# HTNB32L-XXX register map
File version: 0.9
CPU: CM3 r0p0, little endian, no MPU, no FPU, 3 interrupt priority bits
Registers are 32-bit, read-write, reset 0x0 unless marked. A register's access mark holds for its fields unless they carry their own. Offsets are from the block's base; [hi:lo] are bit positions; 'fields as' and 'values as' point back to an identical list.

## IOCON (part 2 of 3) — IOCON pin configuration
Base 0x4002C000
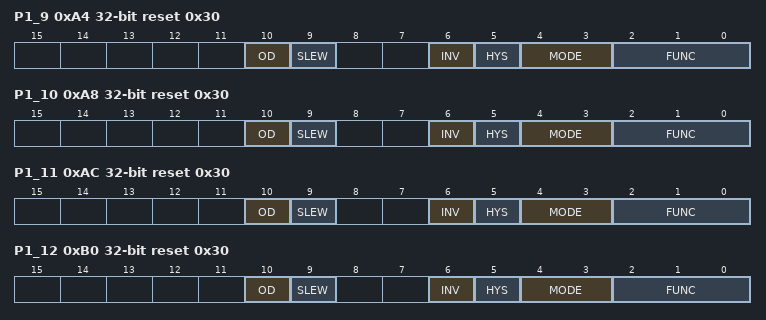
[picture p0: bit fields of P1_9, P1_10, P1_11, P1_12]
0xA4 P1_9 reset 0x30 — I/O configuration register for pin P1[9]
  [10] OD — Open-drain mode.
    0=DISABLE; 1=ENABLED (Open-drain mode enabled. This is not a true open-drain mode. Input cannot be pulled up above VDD.)
  [9] SLEW — Driver slew rate
    0=STANDARD (Standard mode, output slew rate control is enabled. More outputs can be switched simultaneously.); 1=FAST (Fast mode, slew rate control is disabled. Refer to the appropriate specific device data sheet for details.)
  [6] INV — Invert input
    0=INPUT_NOT_INVERTED (Input not inverted (HIGH on pin reads as 1, LOW on pin reads as 0).); 1=INPUT_INVERTED_HIGH (Input inverted (HIGH on pin reads as 0, LOW on pin reads as 1).)
  [5] HYS — Hysteresis.
    0=DISABLE; 1=ENABLE
  [4:3] MODE — Selects function mode (on-chip pull-up/pull-down resistor control).
    0=INACTIVE (Inactive (no pull-down/pull-up resistor enabled).); 1=PULLDOWN_EN (Pull-down resistor enabled.); 2=PULLUP_EN (Pull-up resistor enabled.); 3=REPEATER_MODE
  [2:0] FUNC — Selects pin function for pin P1[9]
    0=P1_9 (General purpose digital input/output pin.); 1=ENET_RXD0 (Ethernet receive data 0 (RMII/MII interface).); 3=T3_MAT0 (Match output for Timer 3, channel 0.)
0xA8 P1_10 reset 0x30 — I/O configuration register for pin P1[10]
  [10] OD — Open-drain mode.
    values as P1_9.OD
  [9] SLEW — Driver slew rate
    values as P1_9.SLEW
  [6] INV — Invert input
    values as P1_9.INV
  [5] HYS — Hysteresis.
    0=DISABLE; 1=ENABLE
  [4:3] MODE — Selects function mode (on-chip pull-up/pull-down resistor control).
    values as P1_9.MODE
  [2:0] FUNC — Selects pin function for pin P1[10]
    0=P1_10 (General purpose digital input/output pin.); 1=ENET_RXD1 (Ethernet receive data 1 (RMII/MII interface).); 3=T3_CAP0 (Capture input for Timer 3, channel 0.)
0xAC P1_11 reset 0x30 — I/O configuration register for pin P1[11]
  [10] OD — Open-drain mode.
    values as P1_9.OD
  [9] SLEW — Driver slew rate
    values as P1_9.SLEW
  [6] INV — Invert input
    values as P1_9.INV
  [5] HYS — Hysteresis.
    0=DISABLE; 1=ENABLE
  [4:3] MODE — Selects function mode (on-chip pull-up/pull-down resistor control).
    values as P1_9.MODE
  [2:0] FUNC — Selects pin function for pin P1[11]
    0=P1_11 (General purpose digital input/output pin.); 1=ENET_RXD2 (Ethernet Receive Data 2 (MII interface).); 2=SD_DAT_2 (Data line 2 for SD card interface.); 3=PWM0_6 (Pulse Width Modulator 0, output 6.)
0xB0 P1_12 reset 0x30 — I/O configuration register for pin P1[12]
  [10] OD — Open-drain mode.
    values as P1_9.OD
  [9] SLEW — Driver slew rate
    values as P1_9.SLEW
  [6] INV — Invert input
    values as P1_9.INV
  [5] HYS — Hysteresis.
    0=DISABLE; 1=ENABLE
  [4:3] MODE — Selects function mode (on-chip pull-up/pull-down resistor control).
    values as P1_9.MODE
  [2:0] FUNC — Selects pin function for pin P1[12]
    0=P1_12 (General purpose digital input/output pin.); 1=ENET_RXD3 (Ethernet Receive Data (MII interface).); 2=SD_DAT_3 (Data line 3 for SD card interface.); 3=PWM0_CAP0 (Capture input for PWM0, channel 0.)
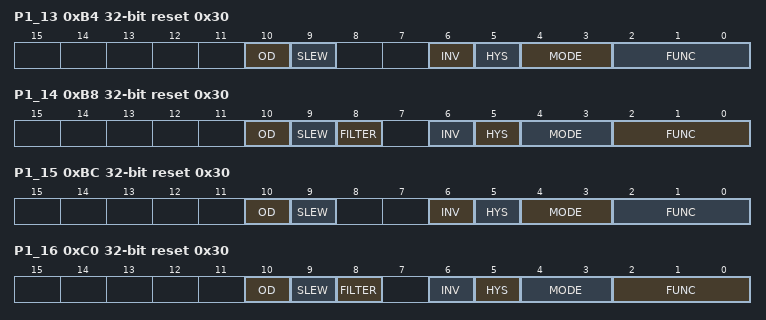
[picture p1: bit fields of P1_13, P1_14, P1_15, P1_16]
0xB4 P1_13 reset 0x30 — I/O configuration register for pin P1[13]
  [10] OD — Open-drain mode.
    values as P1_9.OD
  [9] SLEW — Driver slew rate
    values as P1_9.SLEW
  [6] INV — Invert input
    values as P1_9.INV
  [5] HYS — Hysteresis.
    0=DISABLE; 1=ENABLE
  [4:3] MODE — Selects function mode (on-chip pull-up/pull-down resistor control).
    values as P1_9.MODE
  [2:0] FUNC — Selects pin function for pin P1[13]
    0=P1_13 (General purpose digital input/output pin.); 1=ENET_RX_DV (Ethernet Receive Data Valid (MII interface).)
0xB8 P1_14 reset 0x30 — I/O configuration register for pin P1[14]
  [10] OD — Open-drain mode.
    values as P1_9.OD
  [9] SLEW — Driver slew rate
    values as P1_9.SLEW
  [8] FILTER — Glitch filter control
    0=ENABLED (Noise pulses below approximately 10 ns are filtered out.); 1=DISABLED (No input filtering is done.)
  [6] INV — Invert input
    values as P1_9.INV
  [5] HYS — Hysteresis.
    0=DISABLE; 1=ENABLE
  [4:3] MODE — Selects function mode (on-chip pull-up/pull-down resistor control).
    values as P1_9.MODE
  [2:0] FUNC — Selects pin function for pin P1[14]
    0=P1_14 (General purpose digital input/output pin.); 1=ENET_RX_ER (Ethernet receive error (RMII/MII interface).); 3=T2_CAP0 (Capture input for Timer 2, channel 0.)
0xBC P1_15 reset 0x30 — I/O configuration register for pin P1[15]
  [10] OD — Open-drain mode.
    values as P1_9.OD
  [9] SLEW — Driver slew rate
    values as P1_9.SLEW
  [6] INV — Invert input
    values as P1_9.INV
  [5] HYS — Hysteresis.
    0=DISABLE; 1=ENABLE
  [4:3] MODE — Selects function mode (on-chip pull-up/pull-down resistor control).
    values as P1_9.MODE
  [2:0] FUNC — Selects pin function for pin P1[15]
    0=P1_15 (General purpose digital input/output pin.); 1=ENET_RX_CLK_REF_CLK (Ethernet Receive Clock (MII interface) or Ethernet Reference Clock (RMII interface).); 3=I2C2_SDA (I2C2 data input/output (this pin does not use a specialized I2C pad).)
0xC0 P1_16 reset 0x30 — I/O configuration register for pin P1[16]
  [10] OD — Open-drain mode.
    values as P1_9.OD
  [9] SLEW — Driver slew rate
    values as P1_9.SLEW
  [8] FILTER — Glitch filter control
    values as P1_14.FILTER
  [6] INV — Invert input
    values as P1_9.INV
  [5] HYS — Hysteresis.
    0=DISABLE; 1=ENABLE
  [4:3] MODE — Selects function mode (on-chip pull-up/pull-down resistor control).
    values as P1_9.MODE
  [2:0] FUNC — Selects pin function for pin P1[16]
    0=P1_16 (General purpose digital input/output pin.); 1=ENET_MDC (Ethernet MIIM clock.); 2=I2S_TX_MCLK (I2S transmit master clock.)
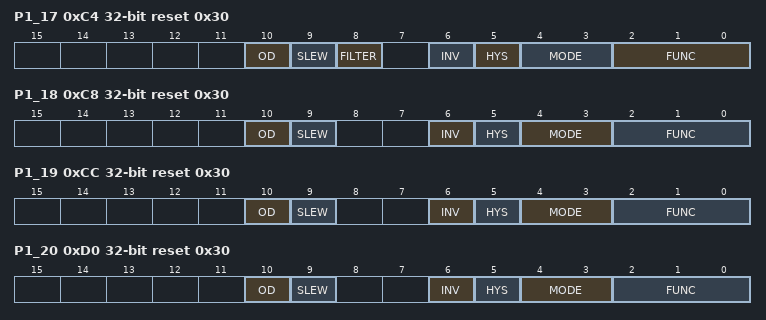
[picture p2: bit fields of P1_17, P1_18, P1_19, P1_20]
0xC4 P1_17 reset 0x30 — I/O configuration register for pin P1[17]
  [10] OD — Open-drain mode.
    values as P1_9.OD
  [9] SLEW — Driver slew rate
    values as P1_9.SLEW
  [8] FILTER — Glitch filter control
    values as P1_14.FILTER
  [6] INV — Invert input
    values as P1_9.INV
  [5] HYS — Hysteresis.
    0=DISABLE; 1=ENABLE
  [4:3] MODE — Selects function mode (on-chip pull-up/pull-down resistor control).
    values as P1_9.MODE
  [2:0] FUNC — Selects pin function for pin P1[17]
    0=P1_17 (General purpose digital input/output pin.); 1=ENET_MDIO (Ethernet MIIM data input and output.); 2=I2S_RX_MCLK (I2S receive master clock.)
0xC8 P1_18 reset 0x30 — I/O configuration register for pin P1[18]
  [10] OD — Open-drain mode.
    values as P1_9.OD
  [9] SLEW — Driver slew rate
    values as P1_9.SLEW
  [6] INV — Invert input
    values as P1_9.INV
  [5] HYS — Hysteresis.
    0=DISABLE; 1=ENABLE
  [4:3] MODE — Selects function mode (on-chip pull-up/pull-down resistor control).
    values as P1_9.MODE
  [2:0] FUNC — Selects pin function for pin P1[18]
    0=P1_18 (General purpose digital input/output pin.); 1=USB_UP_LED1 (It is LOW when the device is configured (non-control endpoints enabled), or when the host is enabled and has detected a device on the bus. It is HIGH when the device is not configured, or when host is enabled and has not detected a device on the bus, or during global suspend. It transitions between LOW and HIGH (flashes) when the host is enabled and detects activity on the bus.); 2=PWM1_1 (Pulse Width Modulator 1, channel 1 output.); 3=T1_CAP0 (Capture input for Timer 1, channel 0.); 5=SSP1_MISO (Master In Slave Out for SSP1.)
0xCC P1_19 reset 0x30 — I/O configuration register for pin P1[19]
  [10] OD — Open-drain mode.
    values as P1_9.OD
  [9] SLEW — Driver slew rate
    values as P1_9.SLEW
  [6] INV — Invert input
    values as P1_9.INV
  [5] HYS — Hysteresis.
    0=DISABLE; 1=ENABLE
  [4:3] MODE — Selects function mode (on-chip pull-up/pull-down resistor control).
    values as P1_9.MODE
  [2:0] FUNC — Selects pin function for pin P1[19]
    0=P1_19 (General purpose digital input/output pin.); 1=USB_TX_E1 (Transmit Enable signal for USB port 1 (OTG transceiver).); 2=USB_PPWR1 (Port Power enable signal for USB port 1.); 3=T1_CAP1 (Capture input for Timer 1, channel 1.); 4=MC_0A (Motor control PWM channel 0, output A.); 5=SSP1_SCK (Serial clock for SSP1.); 6=U2_OE (RS-485/EIA-485 output enable signal for UART2.)
0xD0 P1_20 reset 0x30 — I/O configuration register for pin P1[20]
  [10] OD — Open-drain mode.
    values as P1_9.OD
  [9] SLEW — Driver slew rate
    values as P1_9.SLEW
  [6] INV — Invert input
    values as P1_9.INV
  [5] HYS — Hysteresis.
    0=DISABLE; 1=ENABLE
  [4:3] MODE — Selects function mode (on-chip pull-up/pull-down resistor control).
    values as P1_9.MODE
  [2:0] FUNC — Selects pin function for pin P1[20]
    0=P1_20 (General purpose digital input/output pin.); 1=USB_TX_DP1 (D+ transmit data for USB port 1 (OTG transceiver).); 2=PWM1_2 (Pulse Width Modulator 1, channel 2 output.); 3=QEI_PHA (Quadrature Encoder Interface PHA input.); 4=MC_FB0 (Motor control PWM channel 0 feedback input.); 5=SSP0_SCK (Serial clock for SSP0.); 6=LCD_VD_6 (LCD data.); 7=LCD_VD_10 (LCD data.)
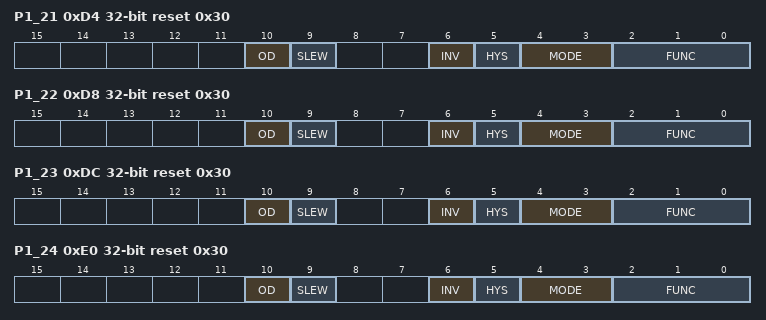
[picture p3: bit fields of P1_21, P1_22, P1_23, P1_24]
0xD4 P1_21 reset 0x30 — I/O configuration register for pin P1[21]
  [10] OD — Open-drain mode.
    values as P1_9.OD
  [9] SLEW — Driver slew rate
    values as P1_9.SLEW
  [6] INV — Invert input
    values as P1_9.INV
  [5] HYS — Hysteresis.
    0=DISABLE; 1=ENABLE
  [4:3] MODE — Selects function mode (on-chip pull-up/pull-down resistor control).
    values as P1_9.MODE
  [2:0] FUNC — Selects pin function for pin P1[21]
    0=P1_21 (General purpose digital input/output pin.); 1=USB_TX_DM1 (D- transmit data for USB port 1 (OTG transceiver).); 2=PWM1_3 (Pulse Width Modulator 1, channel 3 output.); 3=SSP0_SSEL (Slave Select for SSP0.); 4=MC_ABORT (Motor control PWM, active low fast abort.); 6=LCD_VD_7 (LCD data.); 7=LCD_VD_11 (LCD data.)
0xD8 P1_22 reset 0x30 — I/O configuration register for pin P1[22]
  [10] OD — Open-drain mode.
    values as P1_9.OD
  [9] SLEW — Driver slew rate
    values as P1_9.SLEW
  [6] INV — Invert input
    values as P1_9.INV
  [5] HYS — Hysteresis.
    0=DISABLE; 1=ENABLE
  [4:3] MODE — Selects function mode (on-chip pull-up/pull-down resistor control).
    values as P1_9.MODE
  [2:0] FUNC — Selects pin function for pin P1[22]
    0=P1_22 (General purpose digital input/output pin.); 1=USB_RCV1 (Differential receive data for USB port 1 (OTG transceiver).); 2=USB_PWRD1 (Power Status for USB port 1 (host power switch).); 3=T1_MAT0 (Match output for Timer 1, channel 0.); 4=MC_0B (Motor control PWM channel 0, output B.); 5=SSP1_MOSI (Master Out Slave In for SSP1.); 6=LCD_VD_8 (LCD data.); 7=LCD_VD_12 (LCD data.)
0xDC P1_23 reset 0x30 — I/O configuration register for pin P1[23]
  [10] OD — Open-drain mode.
    values as P1_9.OD
  [9] SLEW — Driver slew rate
    values as P1_9.SLEW
  [6] INV — Invert input
    values as P1_9.INV
  [5] HYS — Hysteresis.
    0=DISABLE; 1=ENABLE
  [4:3] MODE — Selects function mode (on-chip pull-up/pull-down resistor control).
    values as P1_9.MODE
  [2:0] FUNC — Selects pin function for pin P1[23]
    0=P1_23 (General purpose digital input/output pin.); 1=USB_RX_DP1 (D+ receive data for USB port 1 (OTG transceiver).); 2=PWM1_4 (Pulse Width Modulator 1, channel 4 output.); 3=QEI_PHB (Quadrature Encoder Interface PHB input.); 4=MC_FB1 (Motor control PWM channel 1 feedback input.); 5=SSP0_MISO (Master In Slave Out for SSP0.); 6=LCD_VD_9 (LCD data.); 7=LCD_VD_13 (LCD data.)
0xE0 P1_24 reset 0x30 — I/O configuration register for pin P1[24]
  [10] OD — Open-drain mode.
    values as P1_9.OD
  [9] SLEW — Driver slew rate
    values as P1_9.SLEW
  [6] INV — Invert input
    values as P1_9.INV
  [5] HYS — Hysteresis.
    0=DISABLE; 1=ENABLE
  [4:3] MODE — Selects function mode (on-chip pull-up/pull-down resistor control).
    values as P1_9.MODE
  [2:0] FUNC — Selects pin function for pin P1[24]
    0=P1_24 (General purpose digital input/output pin.); 1=USB_RX_DM1 (D- receive data for USB port 1 (OTG transceiver).); 2=PWM1_5 (Pulse Width Modulator 1, channel 5 output.); 3=QEI_IDX (Quadrature Encoder Interface INDEX input.); 4=MC_FB2 (Motor control PWM channel 2 feedback input.); 5=SSP0_MOSI (Master Out Slave in for SSP0.); 6=LCD_VD_10 (LCD data.); 7=LCD_VD_14 (LCD data.)
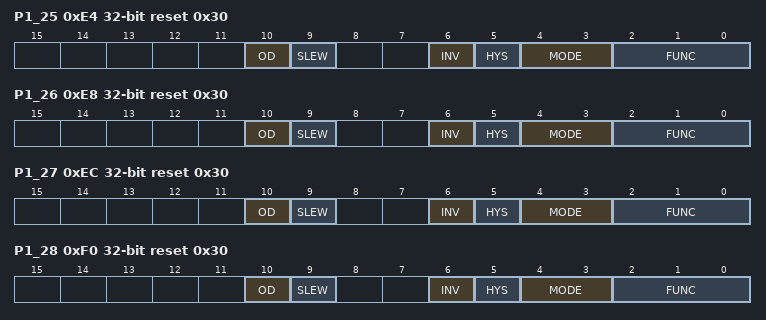
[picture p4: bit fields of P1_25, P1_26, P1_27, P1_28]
0xE4 P1_25 reset 0x30 — I/O configuration register for pin P1[25]
  [10] OD — Open-drain mode.
    values as P1_9.OD
  [9] SLEW — Driver slew rate
    values as P1_9.SLEW
  [6] INV — Invert input
    values as P1_9.INV
  [5] HYS — Hysteresis.
    0=DISABLE; 1=ENABLE
  [4:3] MODE — Selects function mode (on-chip pull-up/pull-down resistor control).
    values as P1_9.MODE
  [2:0] FUNC — Selects pin function for pin P1[25]
    0=P1_25 (General purpose digital input/output pin.); 1=USB_LS1 (Low Speed status for USB port 1 (OTG transceiver).); 2=USB_HSTEN1 (Host Enabled status for USB port 1.); 3=T1_MAT1 (Match output for Timer 1, channel 1.); 4=MC_1A (Motor control PWM channel 1, output A.); 5=CLKOUT (Selectable clock output.); 6=LCD_VD_11 (LCD data.); 7=LCD_VD_15 (LCD data.)
0xE8 P1_26 reset 0x30 — I/O configuration register for pin P1[26]
  [10] OD — Open-drain mode.
    values as P1_9.OD
  [9] SLEW — Driver slew rate
    values as P1_9.SLEW
  [6] INV — Invert input
    values as P1_9.INV
  [5] HYS — Hysteresis.
    0=DISABLE; 1=ENABLE
  [4:3] MODE — Selects function mode (on-chip pull-up/pull-down resistor control).
    values as P1_9.MODE
  [2:0] FUNC — Selects pin function for pin P1[26]
    0=P1_26 (General purpose digital input/output pin.); 1=USB_SSPND1 (USB port 1 Bus Suspend status (OTG transceiver).); 2=PWM1_6 (Pulse Width Modulator 1, channel 6 output.); 3=T0_CAP0 (Capture input for Timer 0, channel 0.); 4=MC_1B (Motor control PWM channel 1, output B.); 5=SSP1_SSEL (Slave Select for SSP1.); 6=LCD_VD_12 (LCD data.); 7=LCD_VD_20 (LCD data.)
0xEC P1_27 reset 0x30 — I/O configuration register for pin P1[27]
  [10] OD — Open-drain mode.
    values as P1_9.OD
  [9] SLEW — Driver slew rate
    values as P1_9.SLEW
  [6] INV — Invert input
    values as P1_9.INV
  [5] HYS — Hysteresis.
    0=DISABLE; 1=ENABLE
  [4:3] MODE — Selects function mode (on-chip pull-up/pull-down resistor control).
    values as P1_9.MODE
  [2:0] FUNC — Selects pin function for pin P1[27]
    0=P1_27 (General purpose digital input/output pin.); 1=USB_INT1 (USB port 1 OTG transceiver interrupt (OTG transceiver).); 2=USB_OVRCR1 (USB port 1 Over-Current status.); 3=T0_CAP1 (Capture input for Timer 0, channel 1.); 4=CLKOUT (Selectable clock output.); 6=LCD_VD_13 (LCD data.); 7=LCD_VD_21 (LCD data.)
0xF0 P1_28 reset 0x30 — I/O configuration register for pin P1[28]
  [10] OD — Open-drain mode.
    values as P1_9.OD
  [9] SLEW — Driver slew rate
    values as P1_9.SLEW
  [6] INV — Invert input
    values as P1_9.INV
  [5] HYS — Hysteresis.
    0=DISABLE; 1=ENABLE
  [4:3] MODE — Selects function mode (on-chip pull-up/pull-down resistor control).
    values as P1_9.MODE
  [2:0] FUNC — Selects pin function for pin P1[28]
    0=P1_28 (General purpose digital input/output pin.); 1=USB_SCL1 (USB port 1 I2C serial clock (OTG transceiver).); 2=PWM1_CAP0 (Capture input for PWM1, channel 0.); 3=T0_MAT0 (Match output for Timer 0, channel 0.); 4=MC_2A (Motor control PWM channel 2, output A.); 5=SSP0_SSEL (Slave Select for SSP0.); 6=LCD_VD_14 (LCD data.); 7=LCD_VD_22 (LCD data.)
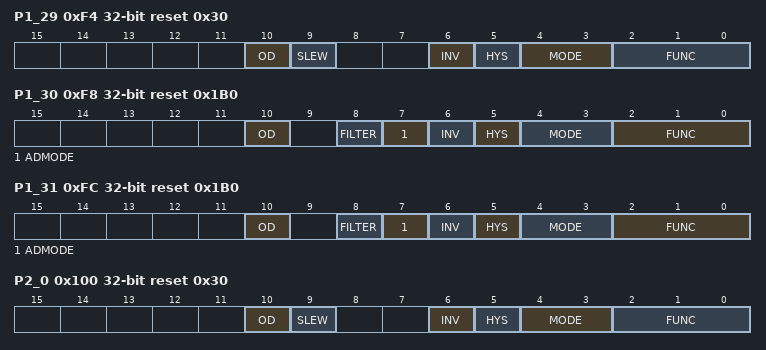
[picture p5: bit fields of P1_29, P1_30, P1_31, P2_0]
0xF4 P1_29 reset 0x30 — I/O configuration register for pin P1[29]
  [10] OD — Open-drain mode.
    values as P1_9.OD
  [9] SLEW — Driver slew rate
    values as P1_9.SLEW
  [6] INV — Invert input
    values as P1_9.INV
  [5] HYS — Hysteresis.
    0=DISABLE; 1=ENABLE
  [4:3] MODE — Selects function mode (on-chip pull-up/pull-down resistor control).
    values as P1_9.MODE
  [2:0] FUNC — Selects pin function for pin P1[29]
    0=P1_29 (General purpose digital input/output pin.); 1=USB_SDA1 (USB port 1 I2C serial data (OTG transceiver).); 2=PWM1_CAP1 (Capture input for PWM1, channel 1.); 3=T0_MAT1 (Match output for Timer 0, channel 1.); 4=MC_2B (Motor control PWM channel 2, output B.); 5=U4_TXD (Transmitter output for USART4 (input/output in smart card mode).); 6=LCD_VD_15 (LCD data.); 7=LCD_VD_23 (LCD data.)
0xF8 P1_30 reset 0x1B0 — I/O configuration register for pin P1[30]
  [10] OD — Open-drain mode.
    0=DISABLE; 1=ENABLED (Open-drain mode enabled. This is not a true open-drain mode.)
  [8] FILTER — Selects 10 ns input glitch filter.
    0=FILTER_DISABLED; 1=FILTER_ENABLED
  [7] ADMODE — Selects Analog/Digital mode.
    0=ANALOG_INPUT_MODE; 1=DIGITAL_FUNCTIONAL_M (Digital functional mode.)
  [6] INV — Invert input
    values as P1_9.INV
  [5] HYS — Hysteresis.
    0=DISABLE; 1=ENABLE
  [4:3] MODE — Selects function mode (on-chip pull-up/pull-down resistor control).
    values as P1_9.MODE
  [2:0] FUNC — Selects pin function for pin P1[30]
    0=P1_30 (General purpose digital input/output pin.); 1=USB_PWRD2 (Power Status for USB port 2.); 2=USB_VBUS (Monitors the presence of USB bus power.This signal must be HIGH for USB reset to occur.); 3=ADC0_IN_4 (A/D converter 0, input 4. When configured as an ADC input, the digital function of the pin must be disabled.); 4=I2C0_SDA (I2C0 data input/output (this pin does not use a specialized I2C pad.); 5=U3_OE (RS-485/EIA-485 output enable signal for UART3.)
0xFC P1_31 reset 0x1B0 — I/O configuration register for pin P1[31]
  [10] OD — Open-drain mode.
    values as P1_30.OD
  [8] FILTER — Selects 10 ns input glitch filter.
    0=FILTER_DISABLED; 1=FILTER_ENABLED
  [7] ADMODE — Selects Analog/Digital mode.
    values as P1_30.ADMODE
  [6] INV — Invert input
    values as P1_9.INV
  [5] HYS — Hysteresis.
    0=DISABLE; 1=ENABLE
  [4:3] MODE — Selects function mode (on-chip pull-up/pull-down resistor control).
    values as P1_9.MODE
  [2:0] FUNC — Selects pin function for pin P1[31]
    0=P1_31 (General purpose digital input/output pin.); 1=USB_OVRCR2 (Over-Current status for USB port 2.); 2=SSP1_SCK (Serial Clock for SSP1.); 3=ADC0_IN_5 (A/D converter 0, input 5. When configured as an ADC input, the digital function of the pin must be disabled.); 4=I2C0_SCL (I2C0 clock input/output (this pin does not use a specialized I2C pad.)
0x100 P2_0 reset 0x30 — I/O configuration register for pin P2[0]
  [10] OD — Open-drain mode.
    values as P1_9.OD
  [9] SLEW — Driver slew rate
    values as P1_9.SLEW
  [6] INV — Invert input
    values as P1_9.INV
  [5] HYS — Hysteresis.
    0=DISABLE; 1=ENABLE
  [4:3] MODE — Selects function mode (on-chip pull-up/pull-down resistor control).
    values as P1_9.MODE
  [2:0] FUNC — Selects pin function for pin P2[0]
    0=P2_0 (General purpose digital input/output pin.); 1=PWM1_1 (Pulse Width Modulator 1, channel 1 output.); 2=U1_TXD (Transmitter output for UART1.); 7=LCD_PWR (LCD panel power enable.)
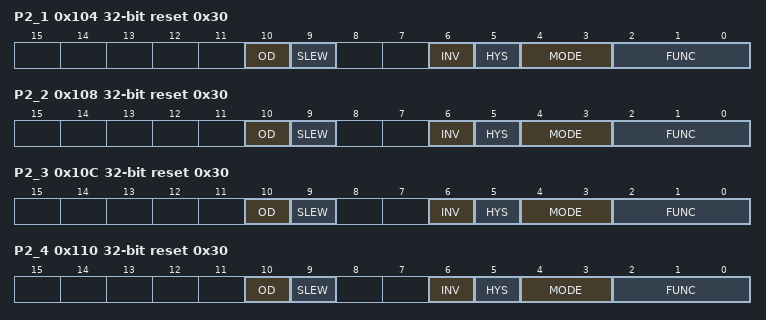
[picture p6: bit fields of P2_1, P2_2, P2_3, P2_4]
0x104 P2_1 reset 0x30 — I/O configuration register for pin P2[1]
  [10] OD — Open-drain mode.
    values as P1_9.OD
  [9] SLEW — Driver slew rate
    values as P1_9.SLEW
  [6] INV — Invert input
    values as P1_9.INV
  [5] HYS — Hysteresis.
    0=DISABLE; 1=ENABLE
  [4:3] MODE — Selects function mode (on-chip pull-up/pull-down resistor control).
    values as P1_9.MODE
  [2:0] FUNC — Selects pin function for pin P2[1]
    0=P2_1 (General purpose digital input/output pin.); 1=PWM1_2 (Pulse Width Modulator 1, channel 2 output.); 2=U1_RXD (Receiver input for UART1.); 7=LCD_LE (Line end signal.)
0x108 P2_2 reset 0x30 — I/O configuration register for pin P2[2]
  [10] OD — Open-drain mode.
    values as P1_9.OD
  [9] SLEW — Driver slew rate
    values as P1_9.SLEW
  [6] INV — Invert input
    values as P1_9.INV
  [5] HYS — Hysteresis.
    0=DISABLE; 1=ENABLE
  [4:3] MODE — Selects function mode (on-chip pull-up/pull-down resistor control).
    values as P1_9.MODE
  [2:0] FUNC — Selects pin function for pin P2[2]
    0=P2_2 (General purpose digital input/output pin.); 1=PWM1_3 (Pulse Width Modulator 1, channel 3 output.); 2=U1_CTS (Clear to Send input for UART1.); 3=T2_MAT3 (Match output for Timer 2, channel 3.); 5=TRACEDATA_3 (Trace data, bit 3.); 7=LCD_DCLK (LCD panel clock.)
0x10C P2_3 reset 0x30 — I/O configuration register for pin P2[3]
  [10] OD — Open-drain mode.
    values as P1_9.OD
  [9] SLEW — Driver slew rate
    values as P1_9.SLEW
  [6] INV — Invert input
    values as P1_9.INV
  [5] HYS — Hysteresis.
    0=DISABLE; 1=ENABLE
  [4:3] MODE — Selects function mode (on-chip pull-up/pull-down resistor control).
    values as P1_9.MODE
  [2:0] FUNC — Selects pin function for pin P2[3]
    0=P2_3 (General purpose digital input/output pin.); 1=PWM1_4 (Pulse Width Modulator 1, channel 4 output.); 2=U1_DCD (Data Carrier Detect input for UART1.); 3=T2_MAT2 (Match output for Timer 2, channel 2.); 5=TRACEDATA_2 (Trace data, bit 2.); 7=LCD_FP (Frame pulse (STN). Vertical synchronization pulse (TFT).)
0x110 P2_4 reset 0x30 — I/O configuration register for pin P2[4]
  [10] OD — Open-drain mode.
    values as P1_9.OD
  [9] SLEW — Driver slew rate
    values as P1_9.SLEW
  [6] INV — Invert input
    values as P1_9.INV
  [5] HYS — Hysteresis.
    0=DISABLE; 1=ENABLE
  [4:3] MODE — Selects function mode (on-chip pull-up/pull-down resistor control).
    values as P1_9.MODE
  [2:0] FUNC — Selects pin function for pin P2[4]
    0=P2_4 (General purpose digital input/output pin.); 1=PWM1_5 (Pulse Width Modulator 1, channel 5 output.); 2=U1_DSR (Data Set Ready input for UART1.); 3=T2_MAT1 (Match output for Timer 2, channel 1.); 5=TRACEDATA_1 (Trace data, bit 1.); 7=LCD_ENAB_M (STN AC bias drive or TFT data enable output.)
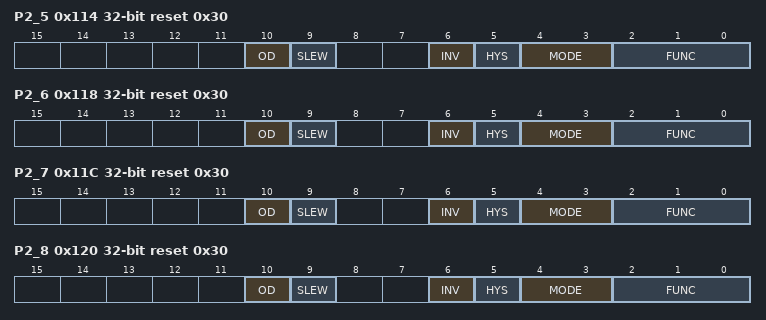
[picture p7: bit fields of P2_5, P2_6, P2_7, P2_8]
0x114 P2_5 reset 0x30 — I/O configuration register for pin P2[5]
  [10] OD — Open-drain mode.
    values as P1_9.OD
  [9] SLEW — Driver slew rate
    values as P1_9.SLEW
  [6] INV — Invert input
    values as P1_9.INV
  [5] HYS — Hysteresis.
    0=DISABLE; 1=ENABLE
  [4:3] MODE — Selects function mode (on-chip pull-up/pull-down resistor control).
    values as P1_9.MODE
  [2:0] FUNC — Selects pin function for pin P2[5]
    0=P2_5 (General purpose digital input/output pin.); 1=PWM1_6 (Pulse Width Modulator 1, channel 6 output.); 2=U1_DTR (Data Terminal Ready output for UART1. Can also be configured to be an RS-485/EIA-485 output enable signal for UART1.); 3=T2_MAT0 (Match output for Timer 2, channel 0.); 5=TRACEDATA_0 (Trace data, bit 0.); 7=LCD_LP (Line synchronization pulse (STN). Horizontal synchronization pulse (TFT).)
0x118 P2_6 reset 0x30 — I/O configuration register for pin P2[6]
  [10] OD — Open-drain mode.
    values as P1_9.OD
  [9] SLEW — Driver slew rate
    values as P1_9.SLEW
  [6] INV — Invert input
    values as P1_9.INV
  [5] HYS — Hysteresis.
    0=DISABLE; 1=ENABLE
  [4:3] MODE — Selects function mode (on-chip pull-up/pull-down resistor control).
    values as P1_9.MODE
  [2:0] FUNC — Selects pin function for pin P2[6]
    0=P2_6 (General purpose digital input/output pin.); 1=PWM1_CAP0 (Capture input for PWM1, channel 0.); 2=U1_RI (Ring Indicator input for UART1.); 3=T2_CAP0 (Capture input for Timer 2, channel 0.); 4=U2_OE (RS-485/EIA-485 output enable signal for UART2.); 5=TRACECLK (Trace clock.); 6=LCD_VD_0 (LCD data.); 7=LCD_VD_4 (LCD data.)
0x11C P2_7 reset 0x30 — I/O configuration register for pin P2[7]
  [10] OD — Open-drain mode.
    values as P1_9.OD
  [9] SLEW — Driver slew rate
    values as P1_9.SLEW
  [6] INV — Invert input
    values as P1_9.INV
  [5] HYS — Hysteresis.
    0=DISABLE; 1=ENABLE
  [4:3] MODE — Selects function mode (on-chip pull-up/pull-down resistor control).
    values as P1_9.MODE
  [2:0] FUNC — Selects pin function for pin P2[7]
    0=P2_7 (General purpose digital input/output pin.); 1=CAN_RD2 (CAN2 receiver input.); 2=U1_RTS (Request to Send output for UART1. Can also be configured to be an RS-485/EIA-485 output enable signal for UART1.); 6=LCD_VD_1 (LCD data.); 7=LCD_VD_5 (LCD data.)
0x120 P2_8 reset 0x30 — I/O configuration register for pin P2[8]
  [10] OD — Open-drain mode.
    values as P1_9.OD
  [9] SLEW — Driver slew rate
    values as P1_9.SLEW
  [6] INV — Invert input
    values as P1_9.INV
  [5] HYS — Hysteresis.
    0=DISABLE; 1=ENABLE
  [4:3] MODE — Selects function mode (on-chip pull-up/pull-down resistor control).
    values as P1_9.MODE
  [2:0] FUNC — Selects pin function for pin P2[8]
    0=P2_8 (General purpose digital input/output pin.); 1=CAN_TD2 (CAN2 transmitter output.); 2=U2_TXD (Transmitter output for UART2.); 3=U1_CTS (Clear to Send input for UART1.); 4=ENET_MDC (Ethernet MIIM clock.); 6=LCD_VD_2 (LCD data.); 7=LCD_VD_6 (LCD data.)
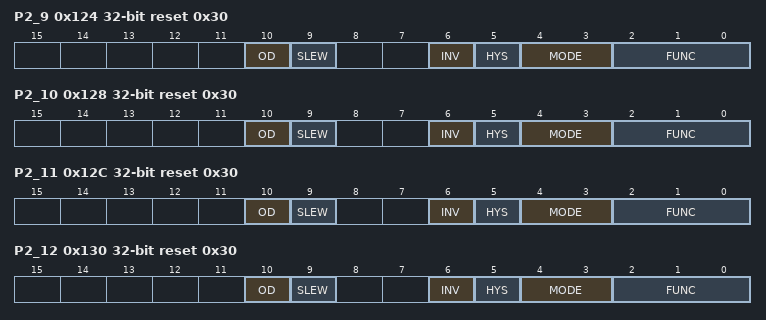
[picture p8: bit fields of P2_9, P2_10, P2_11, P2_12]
0x124 P2_9 reset 0x30 — I/O configuration register for pin P2[9]
  [10] OD — Open-drain mode.
    values as P1_9.OD
  [9] SLEW — Driver slew rate
    values as P1_9.SLEW
  [6] INV — Invert input
    values as P1_9.INV
  [5] HYS — Hysteresis.
    0=DISABLE; 1=ENABLE
  [4:3] MODE — Selects function mode (on-chip pull-up/pull-down resistor control).
    values as P1_9.MODE
  [2:0] FUNC — Selects pin function for pin P2[9]
    0=P2_9 (General purpose digital input/output pin.); 1=USB_CONNECT1 (USB1 SoftConnect control. Signal used to switch an external 1.5 kW resistor under the software control. Used with the SoftConnect USB feature.); 2=U2_RXD (Receiver input for UART2.); 3=U4_RXD (Receiver input for USART4.); 4=ENET_MDIO (Ethernet MIIM data input and output.); 6=LCD_VD_3 (LCD data.); 7=LCD_VD_7 (LCD data.)
0x128 P2_10 reset 0x30 — I/O configuration register for pin P2[10]
  [10] OD — Open-drain mode.
    values as P1_9.OD
  [9] SLEW — Driver slew rate
    values as P1_9.SLEW
  [6] INV — Invert input
    values as P1_9.INV
  [5] HYS — Hysteresis.
    0=DISABLE; 1=ENABLE
  [4:3] MODE — Selects function mode (on-chip pull-up/pull-down resistor control).
    values as P1_9.MODE
  [2:0] FUNC — Selects pin function for pin P2[10]
    0=P2_10 (General purpose digital input/output pin. This pin includes a 5 ns input glitch filter.A LOW on this pin while RESET is LOW forces the on-chip boot loader to take over control of the part after a reset and go into ISP mode.); 1=EINT0 (External interrupt 0 input.); 2=NMI (Non-maskable interrupt input.)
0x12C P2_11 reset 0x30 — I/O configuration register for pin P2[11]
  [10] OD — Open-drain mode.
    values as P1_9.OD
  [9] SLEW — Driver slew rate
    values as P1_9.SLEW
  [6] INV — Invert input
    values as P1_9.INV
  [5] HYS — Hysteresis.
    0=DISABLE; 1=ENABLE
  [4:3] MODE — Selects function mode (on-chip pull-up/pull-down resistor control).
    values as P1_9.MODE
  [2:0] FUNC — Selects pin function for pin P2[11]
    0=P2_11 (General purpose digital input/output pin. This pin includes a 5 ns input glitch filter.); 1=EINT1 (External interrupt 1 input.); 2=SD_DAT_1 (Data line 1 for SD card interface.); 3=I2S_TX_SCK (Transmit Clock. It is driven by the master and received by the slave. Corresponds to the signal SCK in the I2S-bus specification.); 7=LCD_CLKIN (LCD clock.)
0x130 P2_12 reset 0x30 — I/O configuration register for pin P2[12]
  [10] OD — Open-drain mode.
    values as P1_9.OD
  [9] SLEW — Driver slew rate
    values as P1_9.SLEW
  [6] INV — Invert input
    values as P1_9.INV
  [5] HYS — Hysteresis.
    0=DISABLE; 1=ENABLE
  [4:3] MODE — Selects function mode (on-chip pull-up/pull-down resistor control).
    values as P1_9.MODE
  [2:0] FUNC — Selects pin function for pin P2[12]
    0=P2_12 (General purpose digital input/output pin. This pin includes a 5 ns input glitch filter.); 1=EINT2 (External interrupt 2 input.); 2=SD_DAT_2 (Data line 2 for SD card interface.); 3=I2S_TX_WS (Transmit Word Select. It is driven by the master and received by the slave. Corresponds to the signal WS in the I2S-bus specification.); 4=LCD_VD_4 (LCD data.); 5=LCD_VD_3 (LCD data.); 6=LCD_VD_8 (LCD data.); 7=LCD_VD_18 (LCD data.)
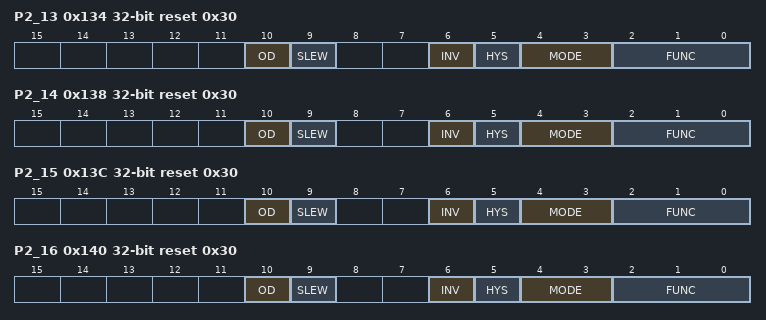
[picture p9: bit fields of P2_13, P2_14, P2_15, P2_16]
0x134 P2_13 reset 0x30 — I/O configuration register for pin P2[13]
  [10] OD — Open-drain mode.
    values as P1_9.OD
  [9] SLEW — Driver slew rate
    values as P1_9.SLEW
  [6] INV — Invert input
    values as P1_9.INV
  [5] HYS — Hysteresis.
    0=DISABLE; 1=ENABLE
  [4:3] MODE — Selects function mode (on-chip pull-up/pull-down resistor control).
    values as P1_9.MODE
  [2:0] FUNC — Selects pin function for pin P2[13]
    0=P2_13 (General purpose digital input/output pin. This pin includes a 5 ns input glitch filter.); 1=EINT3 (External interrupt 3 input.); 2=SD_DAT_3 (Data line 3 for SD card interface.); 3=I2S_TX_SDA (Transmit data. It is driven by the transmitter and read by the receiver. Corresponds to the signal SD in the I2S-bus specification.); 5=LCD_VD_5 (LCD data.); 6=LCD_VD_9 (LCD data.); 7=LCD_VD_19 (LCD data.)
0x138 P2_14 reset 0x30 — I/O configuration register for pin P2[14]
  [10] OD — Open-drain mode.
    values as P1_9.OD
  [9] SLEW — Driver slew rate
    values as P1_9.SLEW
  [6] INV — Invert input
    values as P1_9.INV
  [5] HYS — Hysteresis.
    0=DISABLE; 1=ENABLE
  [4:3] MODE — Selects function mode (on-chip pull-up/pull-down resistor control).
    values as P1_9.MODE
  [2:0] FUNC — Selects pin function for pin P2[14]
    0=P2_14 (General purpose digital input/output pin.); 1=EMC_CS2 (LOW active Chip Select 2 signal.); 2=I2C1_SDA (I2C1 data input/output (this pin does not use a specialized I2C pad).); 3=T2_CAP0 (Capture input for Timer 2, channel 0.)
0x13C P2_15 reset 0x30 — I/O configuration register for pin P2[15]
  [10] OD — Open-drain mode.
    values as P1_9.OD
  [9] SLEW — Driver slew rate
    values as P1_9.SLEW
  [6] INV — Invert input
    values as P1_9.INV
  [5] HYS — Hysteresis.
    0=DISABLE; 1=ENABLE
  [4:3] MODE — Selects function mode (on-chip pull-up/pull-down resistor control).
    values as P1_9.MODE
  [2:0] FUNC — Selects pin function for pin P2[15]
    0=P2_15 (General purpose digital input/output pin.); 1=EMC_CS3 (LOW active Chip Select 3 signal.); 2=I2C1_SCL (I2C1 clock input/output (this pin does not use a specialized I2C pad).); 3=T2_CAP1 (Capture input for Timer 2, channel 1.)
0x140 P2_16 reset 0x30 — I/O configuration register for pin P2[16]
  [10] OD — Open-drain mode.
    values as P1_9.OD
  [9] SLEW — Driver slew rate
    values as P1_9.SLEW
  [6] INV — Invert input
    values as P1_9.INV
  [5] HYS — Hysteresis.
    0=DISABLE; 1=ENABLE
  [4:3] MODE — Selects function mode (on-chip pull-up/pull-down resistor control).
    values as P1_9.MODE
  [2:0] FUNC — Selects pin function for pin P2[16]
    0=P2_16 (General purpose digital input/output pin.); 1=EMC_CAS (LOW active SDRAM Column Address Strobe.)
